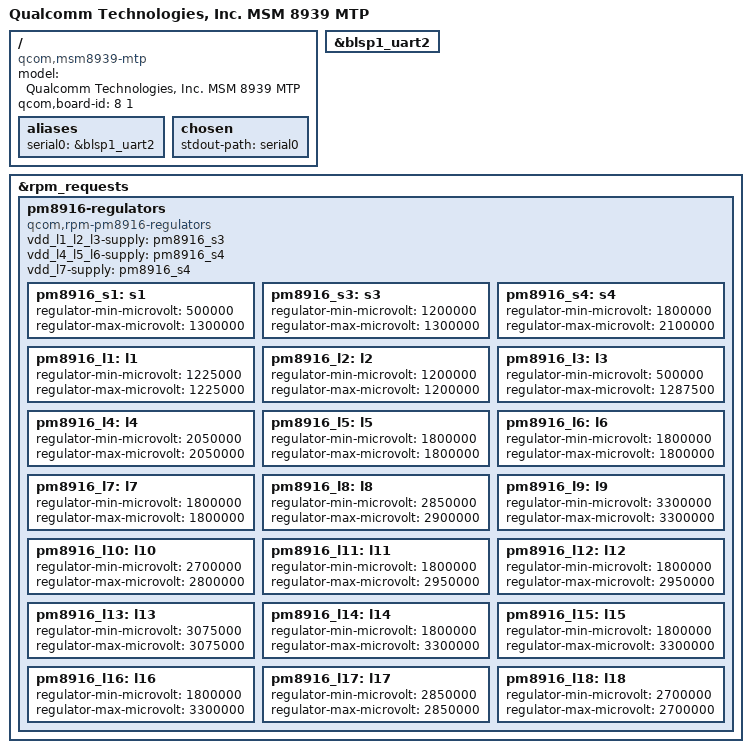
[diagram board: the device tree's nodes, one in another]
// SPDX-License-Identifier: GPL-2.0-only
/*
 * MSM8939 MTP board device tree source
 *
 * Copyright (c) 2020, Pavel Dubrova <pashadubrova@gmail.com>
 */

/dts-v1/;

#include "msm8939.dtsi"

/ {
	model = "Qualcomm Technologies, Inc. MSM 8939 MTP";
	compatible = "qcom,msm8939-mtp";

	qcom,board-id = <8 1>;

	aliases {
		serial0 = &blsp1_uart2;
	};

	chosen {
		stdout-path = "serial0";
	};
};

&blsp1_uart2 {
	status = "okay";
};

&rpm_requests {
	pm8916-regulators {
		compatible = "qcom,rpm-pm8916-regulators";

		vdd_l1_l2_l3-supply = <&pm8916_s3>;
		vdd_l4_l5_l6-supply = <&pm8916_s4>;
		vdd_l7-supply = <&pm8916_s4>;

		pm8916_s1: s1 {
			regulator-min-microvolt = <500000>;
			regulator-max-microvolt = <1300000>;
		};

		pm8916_s3: s3 {
			regulator-min-microvolt = <1200000>;
			regulator-max-microvolt = <1300000>;
		};

		pm8916_s4: s4 {
			regulator-min-microvolt = <1800000>;
			regulator-max-microvolt = <2100000>;
		};

		pm8916_l1: l1 {
			regulator-min-microvolt = <1225000>;
			regulator-max-microvolt = <1225000>;
		};

		pm8916_l2: l2 {
			regulator-min-microvolt = <1200000>;
			regulator-max-microvolt = <1200000>;
		};

		pm8916_l3: l3 {
			regulator-min-microvolt = <500000>;
			regulator-max-microvolt = <1287500>;
		};

		pm8916_l4: l4 {
			regulator-min-microvolt = <2050000>;
			regulator-max-microvolt = <2050000>;
		};

		pm8916_l5: l5 {
			regulator-min-microvolt = <1800000>;
			regulator-max-microvolt = <1800000>;
		};

		pm8916_l6: l6 {
			regulator-min-microvolt = <1800000>;
			regulator-max-microvolt = <1800000>;
		};

		pm8916_l7: l7 {
			regulator-min-microvolt = <1800000>;
			regulator-max-microvolt = <1800000>;
		};

		pm8916_l8: l8 {
			regulator-min-microvolt = <2850000>;
			regulator-max-microvolt = <2900000>;
		};

		pm8916_l9: l9 {
			regulator-min-microvolt = <3300000>;
			regulator-max-microvolt = <3300000>;
		};

		pm8916_l10: l10 {
			regulator-min-microvolt = <2700000>;
			regulator-max-microvolt = <2800000>;
		};

		pm8916_l11: l11 {
			regulator-min-microvolt = <1800000>;
			regulator-max-microvolt = <2950000>;
		};

		pm8916_l12: l12 {
			regulator-min-microvolt = <1800000>;
			regulator-max-microvolt = <2950000>;
		};

		pm8916_l13: l13 {
			regulator-min-microvolt = <3075000>;
			regulator-max-microvolt = <3075000>;
		};

		pm8916_l14: l14 {
			regulator-min-microvolt = <1800000>;
			regulator-max-microvolt = <3300000>;
		};

		pm8916_l15: l15 {
			regulator-min-microvolt = <1800000>;
			regulator-max-microvolt = <3300000>;
		};

		pm8916_l16: l16 {
			regulator-min-microvolt = <1800000>;
			regulator-max-microvolt = <3300000>;
		};

		pm8916_l17: l17 {
			regulator-min-microvolt = <2850000>;
			regulator-max-microvolt = <2850000>;
		};

		pm8916_l18: l18 {
			regulator-min-microvolt = <2700000>;
			regulator-max-microvolt = <2700000>;
		};
	};
};
